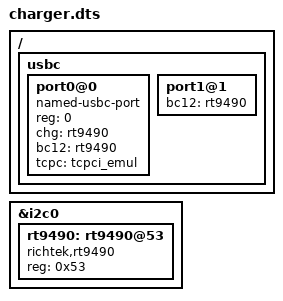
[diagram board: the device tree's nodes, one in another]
/ {
	usbc {
		port0@0 {
			compatible = "named-usbc-port";
			reg = <0>;
			chg = <&rt9490>;
			bc12 = <&rt9490>;
			tcpc = <&tcpci_emul>;
		};

		port1@1 {
			bc12 = <&rt9490>;
		};
	};
};

&i2c0 {
	status = "okay";

	rt9490: rt9490@53 {
		compatible = "richtek,rt9490", "zephyr,rt9490-emul";
		status = "okay";
		reg = <0x53>;
	};
};
